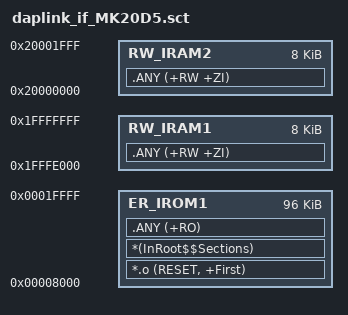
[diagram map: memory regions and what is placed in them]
LR_IROM1 0x00008000 0x00018000  {    ; load region, size (128k - 32k)

  ER_IROM1 0x00008000 0x00018000  {  ; load address = execution address
   *.o (RESET, +First)
   *(InRoot$$Sections)
   .ANY (+RO)
  }
  
  RW_IRAM1 0x1FFFE000 0x00002000  {  ; RW data L (16k/2)
   .ANY (+RW +ZI)
  }
  
  RW_IRAM2 0x20000000 0x00002000  {  ; RW data H (16k/2)
   .ANY (+RW +ZI)
  }
}

